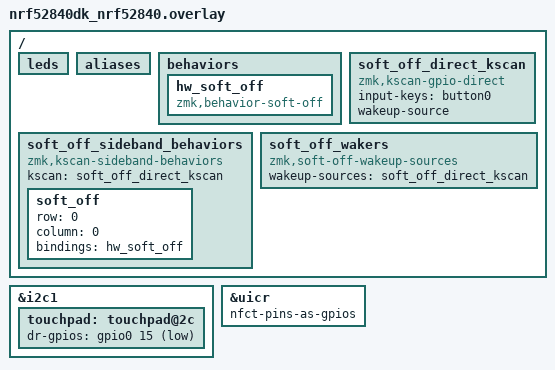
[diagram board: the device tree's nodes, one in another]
/ {
    // First, delete the existing basic GPIO based instance.
    /delete-node/ encoder;
    // Delete led3 which we don't use
    leds {
        /delete-node/ led_3;
    };
    aliases {
        /delete-property/ led3;
    };
};

/ {
    behaviors {
        hw_soft_off: hw_soft_off {
            compatible = "zmk,behavior-soft-off";
            #binding-cells = <0>;
        };
    };

    soft_off_direct_kscan: soft_off_direct_kscan {
        compatible = "zmk,kscan-gpio-direct";
        input-keys = <&button0>;
        wakeup-source;
    };

    soft_off_sideband_behaviors {
        compatible = "zmk,kscan-sideband-behaviors";
        kscan = <&soft_off_direct_kscan>;
        soft_off {
            row = <0>;
            column = <0>;
            bindings = <&hw_soft_off>;
        };
    };

    soft_off_wakers {
        compatible = "zmk,soft-off-wakeup-sources";
        status = "okay";

        wakeup-sources = <&soft_off_direct_kscan>;
    };
};

&i2c1 {
    status = "okay";

    touchpad: touchpad@2c {
        #include "../daisy-touchpad.dtsi"
        dr-gpios = <&gpio0 15 (GPIO_ACTIVE_LOW | GPIO_PULL_UP)>;
    };
};

&uicr {
	// Use 	P0.09 and P0.10 as GPIO for KSO instead of NFC
	nfct-pins-as-gpios;
};
